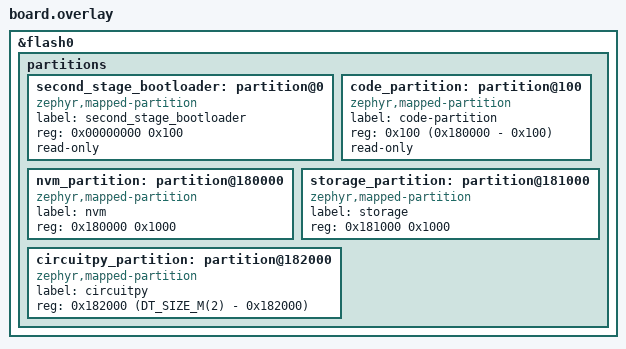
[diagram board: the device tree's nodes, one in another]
&flash0 {
	/delete-node/ partitions;

	partitions {
		ranges;
		#address-cells = <1>;
		#size-cells = <1>;

		/* Reserved memory for the second stage bootloader */
		second_stage_bootloader: partition@0 {
			compatible = "zephyr,mapped-partition";
			label = "second_stage_bootloader";
			reg = <0x00000000 0x100>;
			read-only;
		};

		code_partition: partition@100 {
			compatible = "zephyr,mapped-partition";
			label = "code-partition";
			reg = <0x100 (0x180000 - 0x100)>;
			read-only;
		};

		nvm_partition: partition@180000 {
			compatible = "zephyr,mapped-partition";
			label = "nvm";
			reg = <0x180000 0x1000>;
		};

		storage_partition: partition@181000 {
			compatible = "zephyr,mapped-partition";
			label = "storage";
			reg = <0x181000 0x1000>;
		};

		circuitpy_partition: partition@182000 {
			compatible = "zephyr,mapped-partition";
			label = "circuitpy";
			reg = <0x182000 (DT_SIZE_M(2) - 0x182000)>;
		};
	};
};

#include "../../../app.overlay"
